# GD32F10x_HD register map
File version: 1.0
CPU: CM3 r2p1, little endian, no MPU, no FPU, 4 interrupt priority bits
Registers are 32-bit, read-write, reset 0x0 unless marked. A register's access mark holds for its fields unless they carry their own. Offsets are from the block's base; [hi:lo] are bit positions; {n}, {i} and the like mark numbered series.

## TIMER5 — Basic-timers
Base 0x40001000
Same registers: TIMER6 0x40001400
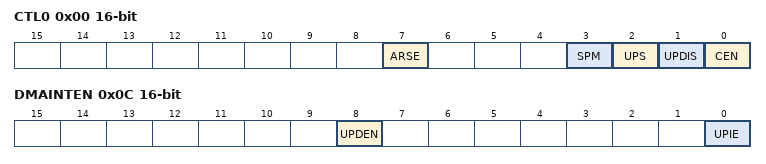
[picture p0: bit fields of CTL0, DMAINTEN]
0x00 CTL0 16-bit — control register 0
  [7] ARSE — Auto-reload shadow enable
  [3] SPM — Single pulse mode
  [2] UPS — Update source
  [1] UPDIS — Update disable
  [0] CEN — Counter enable
0x04 CTL1 16-bit — control register 1
  [6:4] MMC — Master mode control
0x0C DMAINTEN 16-bit — DMA/Interrupt enable register
  [8] UPDEN — Update DMA request enable
  [0] UPIE — Update interrupt enable
0x10 INTF 16-bit — Interrupt flag register
  [0] UPIF — Update interrupt flag
0x14 SWEVG 16-bit wo — event generation register
  [0] UPG — Update generation
0x24 CNT 16-bit — Counter register
  [15:0] CNT — Low counter value
0x28 PSC 16-bit — Prescaler register
  [15:0] PSC — Prescaler value of the counter clock
0x2C CAR 16-bit — Counter auto reload register
  [15:0] CARL — Counter auto reload value

## USART0 — Universal synchronous asynchronous receiver transmitter
Base 0x40013800
Same registers: USART1 0x40004400, USART2 0x40004800
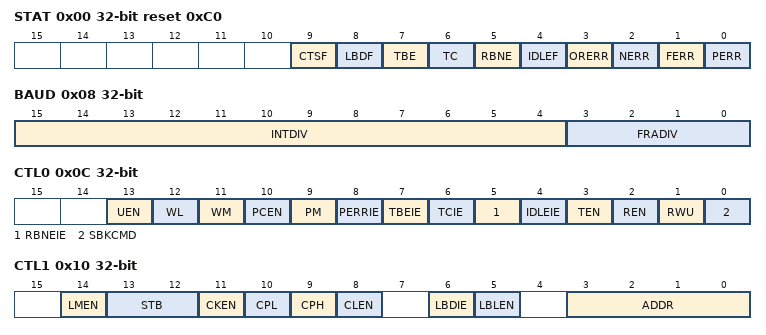
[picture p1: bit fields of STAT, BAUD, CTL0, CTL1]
0x00 STAT access per field reset 0xC0 — Status register
  [9] CTSF rw — CTS change flag
  [8] LBDF rw — LIN break detection flag
  [7] TBE ro — Transmit data buffer empty
  [6] TC rw — Transmission complete
  [5] RBNE rw — Read data buffer not empty
  [4] IDLEF ro — IDLE frame detected flag
  [3] ORERR ro — Overrun error
  [2] NERR ro — Noise error flag
  [1] FERR ro — Frame error flag
  [0] PERR ro — Parity error flag
0x04 DATA
  [8:0] DATA — Transmit or read data value
0x08 BAUD — Baud rate register
  [15:4] INTDIV — Integer part of baud-rate divider
  [3:0] FRADIV — Fraction part of baud-rate divider
0x0C CTL0 — Control register 0
  [13] UEN — USART enable
  [12] WL — Word length
  [11] WM — Wakeup method in mute mode
  [10] PCEN — Parity check function enable
  [9] PM — Parity mode
  [8] PERRIE — Parity error interrupt enable
  [7] TBEIE — Transmitter buffer empty interrupt enable
  [6] TCIE — Transmission complete interrupt enable
  [5] RBNEIE — Read data buffer not empty interrupt and overrun error interrupt enable
  [4] IDLEIE — IDLE line detected interrupt enable
  [3] TEN — Transmitter enable
  [2] REN — Receiver enable
  [1] RWU — Receiver wakeup from mute mode
  [0] SBKCMD — Send break command
0x10 CTL1 — Control register 1
  [14] LMEN — LIN mode enable
  [13:12] STB — STOP bits length
  [11] CKEN — CK pin enable
  [10] CPL — Clock polarity
  [9] CPH — Clock phase
  [8] CLEN — CK Length
  [6] LBDIE — LIN break detection interrupt enable
  [5] LBLEN — LIN break frame length
  [3:0] ADDR — Address of the USART
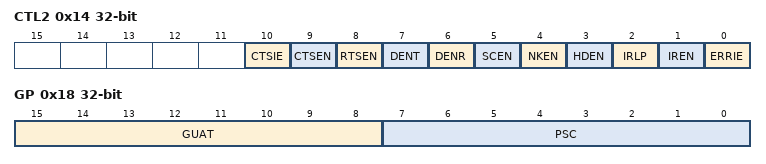
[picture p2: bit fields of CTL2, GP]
0x14 CTL2 — Control register 2
  [10] CTSIE — CTS interrupt enable
  [9] CTSEN — CTS enable
  [8] RTSEN — RTS enable
  [7] DENT — DMA request enable for transmission
  [6] DENR — DMA request enable for reception
  [5] SCEN — Smartcard mode enable
  [4] NKEN — Smartcard NACK enable
  [3] HDEN — Half-duplex selection
  [2] IRLP — IrDA low-power
  [1] IREN — IrDA mode enable
  [0] ERRIE — Error interrupt enable
0x18 GP — Guard time and prescaler register
  [15:8] GUAT — Guard time value in Smartcard mode
  [7:0] PSC — Prescaler value

## UART3 — Universal asynchronous receiver transmitter
Base 0x40004C00
Same registers: UART4 0x40005000
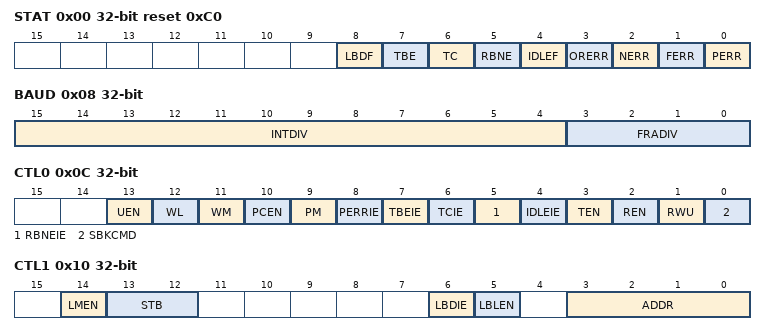
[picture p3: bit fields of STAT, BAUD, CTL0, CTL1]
0x00 STAT access per field reset 0xC0 — Status register
  [8] LBDF rw — LIN break detection flag
  [7] TBE ro — Transmit data buffer empty
  [6] TC rw — Transmission complete
  [5] RBNE rw — Read data buffer not empty
  [4] IDLEF ro — IDLE frame detected flag
  [3] ORERR ro — Overrun error
  [2] NERR ro — Noise error flag
  [1] FERR ro — Frame error flag
  [0] PERR ro — Parity error flag
0x04 DATA
  [8:0] DATA — Transmit or read data value
0x08 BAUD — Baud rate register
  [15:4] INTDIV — Integer part of baud-rate divider
  [3:0] FRADIV — Fraction part of baud-rate divider
0x0C CTL0 — Control register 0
  [13] UEN — USART enable
  [12] WL — Word length
  [11] WM — Wakeup method in mute mode
  [10] PCEN — Parity check function enable
  [9] PM — Parity mode
  [8] PERRIE — Parity error interrupt enable
  [7] TBEIE — Transmitter buffer empty interrupt enable
  [6] TCIE — Transmission complete interrupt enable
  [5] RBNEIE — Read data buffer not empty interrupt and overrun error interrupt enable
  [4] IDLEIE — IDLE line detected interrupt enable
  [3] TEN — Transmitter enable
  [2] REN — Receiver enable
  [1] RWU — Receiver wakeup from mute mode
  [0] SBKCMD — Send break command
0x10 CTL1 — Control register 1
  [14] LMEN — LIN mode enable
  [13:12] STB — STOP bits length
  [6] LBDIE — LIN break detection interrupt enable
  [5] LBLEN — LIN break frame length
  [3:0] ADDR — Address of the USART
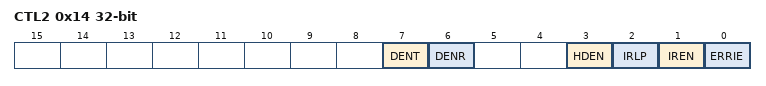
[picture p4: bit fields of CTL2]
0x14 CTL2 — Control register 2
  [7] DENT — DMA request enable for transmission
  [6] DENR — DMA request enable for reception
  [3] HDEN — Half-duplex selection
  [2] IRLP — IrDA low-power
  [1] IREN — IrDA mode enable
  [0] ERRIE — Error interrupt enable
0x18 GP — Guard time and prescaler register
  [7:0] PSC — Prescaler value

## USBD — Universal serial bus full-speed device interface
Base 0x40005C00
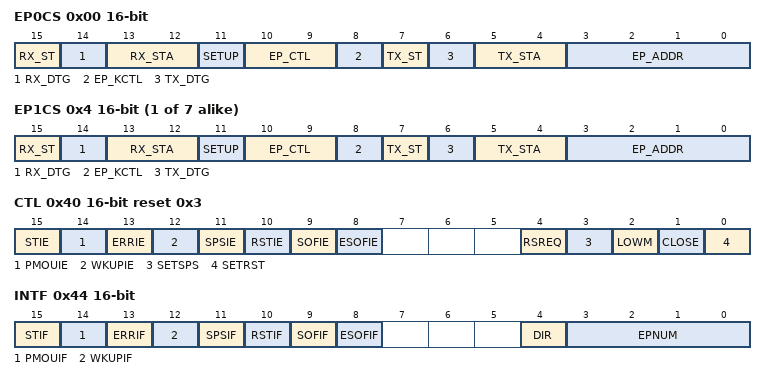
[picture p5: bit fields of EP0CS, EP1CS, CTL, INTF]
0x00 EP0CS 16-bit — endpoint 0 register
  [15] RX_ST — Correct transfer for reception
  [14] RX_DTG — Data Toggle, for reception transfers
  [13:12] RX_STA — Status bits, for reception transfers
  [11] SETUP — Setup transaction completed
  [10:9] EP_CTL — Endpoint type
  [8] EP_KCTL — Endpoint kind
  [7] TX_ST — Correct Transfer for transmission
  [6] TX_DTG — Data PID Toggle, for transmission transfers
  [5:4] TX_STA — Status bits, for transmission transfers
  [3:0] EP_ADDR — Endpoint address
{0x0+4i} EP{i}CS 16-bit (i=1..7) — endpoint {i} register
  [15] RX_ST — Correct transfer for reception
  [14] RX_DTG — Data Toggle, for reception transfers
  [13:12] RX_STA — Status bits, for reception transfers
  [11] SETUP — Setup transaction completed
  [10:9] EP_CTL — Endpoint type
  [8] EP_KCTL — Endpoint kind
  [7] TX_ST — Correct Transfer for transmission
  [6] TX_DTG — Data Toggle, for transmission transfers
  [5:4] TX_STA — Status bits, for transmission transfers
  [3:0] EP_ADDR — Endpoint address
0x40 CTL 16-bit reset 0x3 — control register
  [15] STIE — Successful transfer interrupt enable
  [14] PMOUIE — Packet memory area over / underrun interrupt enable
  [13] ERRIE — Error interrupt mask
  [12] WKUPIE — Wakeup interrupt enable
  [11] SPSIE — Suspend mode interrupt mask
  [10] RSTIE — USB reset interrupt mask
  [9] SOFIE — Start of frame interrupt mask
  [8] ESOFIE — Expected start of frame interrupt enable
  [4] RSREQ — Resume request
  [3] SETSPS — Set suspend
  [2] LOWM — Low-power mode
  [1] CLOSE — Close state
  [0] SETRST — Set reset
0x44 INTF 16-bit access per field — interrupt flag register
  [15] STIF ro — Successful transfer interrupt flag
  [14] PMOUIF rw — Packet memory area over / underrun interrupt flag
  [13] ERRIF rw — Error interrupt flag
  [12] WKUPIF rw — Wakeup interrupt flag
  [11] SPSIF rw — Suspend mode interrupt flag
  [10] RSTIF rw — reset interrupt flag
  [9] SOFIF rw — start of frame interrupt flag
  [8] ESOFIF rw — Expected start of frame interrupt flag
  [4] DIR ro — Direction of transaction
  [3:0] EPNUM ro — Endpoint Identifier
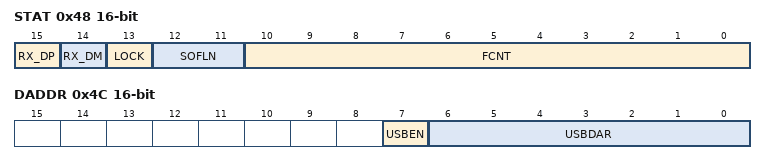
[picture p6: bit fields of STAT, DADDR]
0x48 STAT 16-bit ro — Status register
  [15] RX_DP — Receive data + line status
  [14] RX_DM — Receive data - line status
  [13] LOCK — Locked the USB
  [12:11] SOFLN — Lost SOF number
  [10:0] FCNT — Frame number counter
0x4C DADDR 16-bit — device address register
  [7] USBEN — USB device enable
  [6:0] USBDAR — Device address
0x50 BADDR 16-bit — Buffer address register
  [15:3] BAR — Buffer address

## WWDGT — Window watchdog timer
Base 0x40002C00
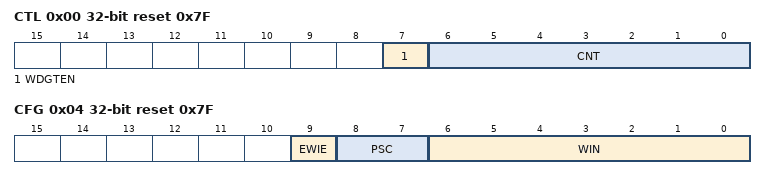
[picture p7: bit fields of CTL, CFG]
0x00 CTL reset 0x7F — Control register
  [7] WDGTEN — Activation bit
  [6:0] CNT — 7-bit counter
0x04 CFG reset 0x7F — Configuration register
  [9] EWIE — Early wakeup interrupt
  [8:7] PSC — Prescaler
  [6:0] WIN — 7-bit window value
0x08 STAT — Status register
  [0] EWIF — Early wakeup interrupt flag
